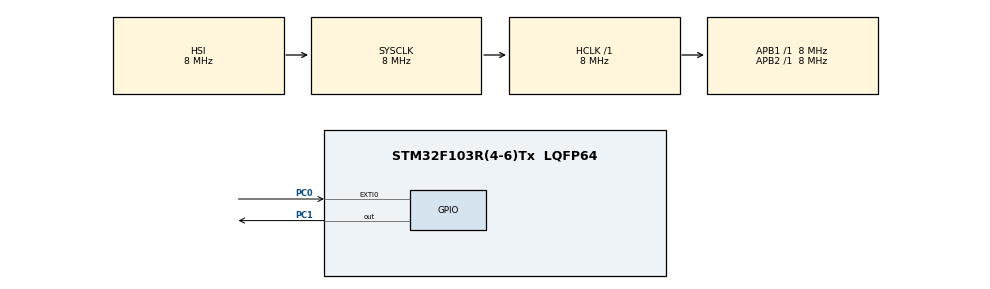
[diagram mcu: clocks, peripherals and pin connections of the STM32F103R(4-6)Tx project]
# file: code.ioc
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Mcu.Family=STM32F1
NVIC.TIM1_UP_IRQn=true\:0\:0\:false\:false\:true\:false\:true
PC0.Signal=GPXTI0
VP_SYS_VS_ND.Mode=No_Debug
ProjectManager.StackSize=0x400
ProjectManager.TargetToolchain=Makefile
RCC.HCLKFreq_Value=8000000
RCC.APB2TimFreq_Value=8000000
RCC.AHBFreq_Value=8000000
RCC.HSE_VALUE=4000000
board=custom
PC1.GPIO_PuPd=GPIO_PULLUP
RCC.APB2Freq_Value=8000000
VP_SYS_VS_tim1.Mode=TIM1
PC1.GPIO_Speed=GPIO_SPEED_FREQ_LOW
Mcu.Name=STM32F103R(4-6)Tx
PC0.GPIO_ModeDefaultEXTI=GPIO_MODE_IT_FALLING
NVIC.EXTI0_IRQn=true\:0\:0\:false\:false\:true\:true\:true
RCC.SYSCLKFreq_VALUE=8000000
Mcu.Package=LQFP64
NVIC.TimeBase=TIM1_UP_IRQn
NVIC.TimeBaseIP=TIM1
ProjectManager.HeapSize=0x200
PC1.GPIO_ModeDefaultOutputPP=GPIO_MODE_OUTPUT_PP
NVIC.PriorityGroup=NVIC_PRIORITYGROUP_2
RCC.APB1TimFreq_Value=8000000
PC0.GPIO_PuPd=GPIO_PULLUP
RCC.APB1Freq_Value=8000000
PC1.Signal=GPIO_Output

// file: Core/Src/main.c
/* USER CODE BEGIN Header */
/**
 ******************************************************************************
 * @file           : main.c
 * @brief          : Main program body
 ******************************************************************************
 * @attention
 *
 * <h2><center>&copy; Copyright (c) 2020 STMicroelectronics.
 * All rights reserved.</center></h2>
 *
 * This software component is licensed by ST under BSD 3-Clause license,
 * the "License"; You may not use this file except in compliance with the
 * License. You may obtain a copy of the License at:
 *                        opensource.org/licenses/BSD-3-Clause
 *
 ******************************************************************************
 */
/* USER CODE END Header */
#include "main.h"
#include "gpio.h"

void SystemClock_Config(void);

/* USER CODE BEGIN 0 */
uint32_t volatile sysClk = 0;
/* USER CODE END 0 */

int main(void) {
	/* USER CODE BEGIN 1 */
	sysClk = SystemCoreClock;
	/* USER CODE END 1 */

	/* MCU Configuration--------------------------------------------------------*/

	/* Reset of all peripherals, Initializes the Flash interface and the Systick. */
	HAL_Init();

	/* USER CODE BEGIN Init */
	sysClk = SystemCoreClock;
	/* USER CODE END Init */

	/* Configure the system clock */
	SystemClock_Config();

	/* USER CODE BEGIN SysInit */
	sysClk = SystemCoreClock;
	/* USER CODE END SysInit */

	/* Initialize all configured peripherals */
	MX_GPIO_Init();
	/* USER CODE BEGIN 2 */
	NVIC_SetPriorityGrouping(5);
	uint32_t priorityGroup = NVIC_GetPriorityGrouping();

	NVIC_SetPriority(WWDG_IRQn, NVIC_EncodePriority(priorityGroup, 1, 2));
	NVIC_EnableIRQ(WWDG_IRQn);

	NVIC_SetPriority(PVD_IRQn, NVIC_EncodePriority(priorityGroup, 1, 0));
	NVIC_EnableIRQ(PVD_IRQn);

	NVIC_SetPriority(TAMPER_IRQn, NVIC_EncodePriority(priorityGroup, 1, 1));
	NVIC_EnableIRQ(TAMPER_IRQn);

	NVIC->ISPR[0] = 0b111;

	sysClk = SystemCoreClock;
	SysTick_Config(sysClk / 2);

	NVIC_SetPriority(SysTick_IRQn, NVIC_EncodePriority(priorityGroup, 0, 0));

	HAL_GPIO_WritePin(GPIOC, GPIO_PIN_1, GPIO_PIN_SET);
	/* USER CODE END 2 */

	/* Infinite loop */
	while (1) {

	}
}

void SystemClock_Config(void) {
	RCC_OscInitTypeDef RCC_OscInitStruct = { 0 };
	RCC_ClkInitTypeDef RCC_ClkInitStruct = { 0 };

	/** Initializes the RCC Oscillators according to the specified parameters
	 * in the RCC_OscInitTypeDef structure.
	 */
	RCC_OscInitStruct.OscillatorType = RCC_OSCILLATORTYPE_HSI;
	RCC_OscInitStruct.HSIState = RCC_HSI_ON;
	RCC_OscInitStruct.HSICalibrationValue = RCC_HSICALIBRATION_DEFAULT;
	RCC_OscInitStruct.PLL.PLLState = RCC_PLL_NONE;
	if (HAL_RCC_OscConfig(&RCC_OscInitStruct) != HAL_OK) {
		Error_Handler();
	}
	/** Initializes the CPU, AHB and APB buses clocks
	 */
	RCC_ClkInitStruct.ClockType = RCC_CLOCKTYPE_HCLK | RCC_CLOCKTYPE_SYSCLK
			| RCC_CLOCKTYPE_PCLK1 | RCC_CLOCKTYPE_PCLK2;
	RCC_ClkInitStruct.SYSCLKSource = RCC_SYSCLKSOURCE_HSI;
	RCC_ClkInitStruct.AHBCLKDivider = RCC_SYSCLK_DIV1;
	RCC_ClkInitStruct.APB1CLKDivider = RCC_HCLK_DIV1;
	RCC_ClkInitStruct.APB2CLKDivider = RCC_HCLK_DIV1;

	if (HAL_RCC_ClockConfig(&RCC_ClkInitStruct, FLASH_LATENCY_0) != HAL_OK) {
		Error_Handler();
	}
}

void HAL_TIM_PeriodElapsedCallback(TIM_HandleTypeDef *htim) {
	if (htim->Instance == TIM1) {
		HAL_IncTick();
	}
}

void Error_Handler(void) {
}

/************************ (C) COPYRIGHT STMicroelectronics *****END OF FILE****/
